# ATSAML22G18A register map
Vendor: Atmel Corporation; Series: SAML22; File version: A
CPU: CM0+ r0p1, little endian, MPU, no FPU, VTOR, 2 interrupt priority bits
Registers are 32-bit, read-write, reset 0x0 unless marked. A register's access mark holds for its fields unless they carry their own. Offsets are from the block's base; [hi:lo] are bit positions; {n}, {i} and the like mark numbered series; 'fields as' and 'values as' point back to an identical list.

## OSC32KCTRL — 32k Oscillators Control
Base 0x40001400; register names take the prefix OSC32KCTRL_
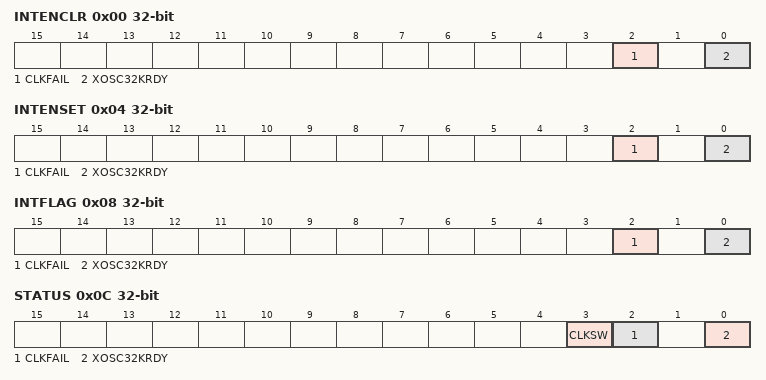
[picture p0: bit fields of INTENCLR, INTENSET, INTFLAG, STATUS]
0x00 INTENCLR — Interrupt Enable Clear
  [2] CLKFAIL — XOSC32K Clock Failure Detector Interrupt Enable
  [0] XOSC32KRDY — XOSC32K Ready Interrupt Enable
0x04 INTENSET — Interrupt Enable Set
  fields as INTENCLR
0x08 INTFLAG — Interrupt Flag Status and Clear
  [2] CLKFAIL — XOSC32K Clock Failure Detector
  [0] XOSC32KRDY — XOSC32K Ready
0x0C STATUS ro — Power and Clocks Status
  [3] CLKSW — XOSC32K Clock switch
  [2] CLKFAIL — XOSC32K Clock Failure Detector
  [0] XOSC32KRDY — XOSC32K Ready
0x10 RTCCTRL 8-bit — RTC Clock Selection
  [2:0] RTCSEL
    0=ULP1K (1.024kHz from 32kHz internal ULP oscillator); 1=ULP32K (32.768kHz from 32kHz internal ULP oscillator); 2=OSC1K (1.024kHz from 32.768kHz internal oscillator); 3=OSC32K (32.768kHz from 32.768kHz internal oscillator); 4=XOSC1K (1.024kHz from 32.768kHz internal oscillator); 5=XOSC32K (32.768kHz from 32.768kHz external crystal oscillator)
0x11 SLCDCTRL 8-bit — SLCD Clock Selection
  [0] SLCDSEL
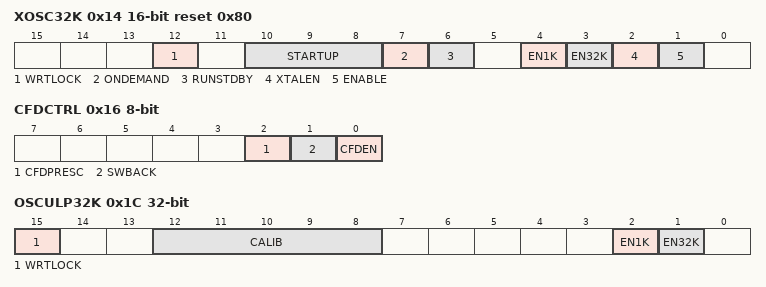
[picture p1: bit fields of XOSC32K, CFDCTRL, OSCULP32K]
0x14 XOSC32K 16-bit reset 0x80 — 32kHz External Crystal Oscillator (XOSC32K) Control
  [12] WRTLOCK — Write Lock
  [10:8] STARTUP — Oscillator Start-Up Time
  [7] ONDEMAND — On Demand Control
  [6] RUNSTDBY — Run in Standby
  [4] EN1K — 1kHz Output Enable
  [3] EN32K — 32kHz Output Enable
  [2] XTALEN — Crystal Oscillator Enable
  [1] ENABLE — Oscillator Enable
0x16 CFDCTRL 8-bit — Clock Failure Detector Control
  [2] CFDPRESC — Clock Failure Detector Prescaler
  [1] SWBACK — Clock Switch Back
  [0] CFDEN — Clock Failure Detector Enable
0x17 EVCTRL 8-bit — Event Control
  [0] CFDEO — Clock Failure Detector Event Output Enable
0x1C OSCULP32K — 32kHz Ultra Low Power Internal Oscillator (OSCULP32K) Control
  [15] WRTLOCK — Write Lock
  [12:8] CALIB — Oscillator Calibration
  [2] EN1K — Enable Out 1k
  [1] EN32K — Enable Out 32k

## PAC — Peripheral Access Controller
Base 0x40000000; register names take the prefix PAC_
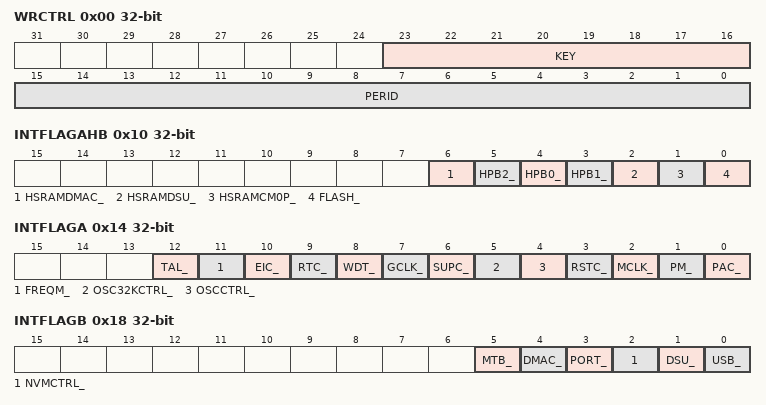
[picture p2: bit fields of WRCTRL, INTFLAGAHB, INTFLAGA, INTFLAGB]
0x00 WRCTRL — Write control
  [23:16] KEY — Peripheral access control key
    0=OFF (No action); 1=CLR (Clear protection); 2=SET (Set protection); 3=SETLCK (Set and lock protection)
  [15:0] PERID — Peripheral identifier
0x04 EVCTRL 8-bit — Event control
  [0] ERREO — Peripheral acess error event output
0x08 INTENCLR 8-bit — Interrupt enable clear
  [0] ERR — Peripheral access error interrupt disable
0x09 INTENSET 8-bit — Interrupt enable set
  [0] ERR — Peripheral access error interrupt enable
0x10 INTFLAGAHB — Bridge interrupt flag status
  [6] HSRAMDMAC_, [5] HPB2_, [4] HPB0_, [3] HPB1_, [2] HSRAMDSU_, [1] HSRAMCM0P_, [0] FLASH_
0x14 INTFLAGA — Peripheral interrupt flag status - Bridge A
  [12] TAL_, [11] FREQM_, [10] EIC_, [9] RTC_, [8] WDT_, [7] GCLK_, [6] SUPC_, [5] OSC32KCTRL_, [4] OSCCTRL_, [3] RSTC_, [2] MCLK_, [1] PM_, [0] PAC_
0x18 INTFLAGB — Peripheral interrupt flag status - Bridge B
  [5] MTB_, [4] DMAC_, [3] PORT_, [2] NVMCTRL_, [1] DSU_, [0] USB_
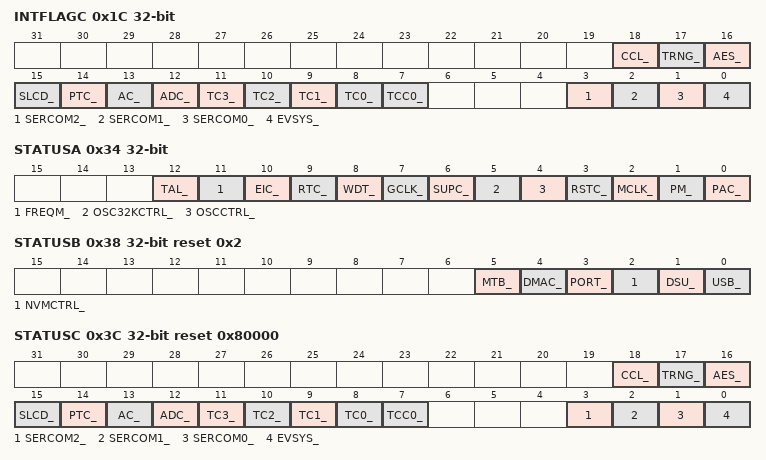
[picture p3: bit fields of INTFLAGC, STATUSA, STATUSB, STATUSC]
0x1C INTFLAGC — Peripheral interrupt flag status - Bridge C
  [18] CCL_, [17] TRNG_, [16] AES_, [15] SLCD_, [14] PTC_, [13] AC_, [12] ADC_, [n+8] TC{n}_ (n=0..3), [7] TCC0_, [3] SERCOM2_, [2] SERCOM1_, [1] SERCOM0_, [0] EVSYS_
0x34 STATUSA ro — Peripheral write protection status - Bridge A
  [12] TAL_ — TAL APB Protect Enable
  [11] FREQM_ — FREQM APB Protect Enable
  [10] EIC_ — EIC APB Protect Enable
  [9] RTC_ — RTC APB Protect Enable
  [8] WDT_ — WDT APB Protect Enable
  [7] GCLK_ — GCLK APB Protect Enable
  [6] SUPC_ — SUPC APB Protect Enable
  [5] OSC32KCTRL_ — OSC32KCTRL APB Protect Enable
  [4] OSCCTRL_ — OSCCTRL APB Protect Enable
  [3] RSTC_ — RSTC APB Protect Enable
  [2] MCLK_ — MCLK APB Protect Enable
  [1] PM_ — PM APB Protect Enable
  [0] PAC_ — PAC APB Protect Enable
0x38 STATUSB ro reset 0x2 — Peripheral write protection status - Bridge B
  [5] MTB_ — MTB APB Protect Enable
  [4] DMAC_ — DMAC APB Protect Enable
  [3] PORT_ — PORT APB Protect Enable
  [2] NVMCTRL_ — NVMCTRL APB Protect Enable
  [1] DSU_ — DSU APB Protect Enable
  [0] USB_ — USB APB Protect Enable
0x3C STATUSC ro reset 0x80000 — Peripheral write protection status - Bridge C
  [18] CCL_ — CCL APB Protect Enable
  [17] TRNG_ — TRNG APB Protect Enable
  [16] AES_ — AES APB Protect Enable
  [15] SLCD_ — SLCD APB Protect Enable
  [14] PTC_ — PTC APB Protect Enable
  [13] AC_ — AC APB Protect Enable
  [12] ADC_ — ADC APB Protect Enable
  [n+8] TC{n}_ (n=0..3) — TC{n} APB Protect Enable
  [7] TCC0_ — TCC0 APB Protect Enable
  [3] SERCOM2_ — SERCOM2 APB Protect Enable
  [2] SERCOM1_ — SERCOM1 APB Protect Enable
  [1] SERCOM0_ — SERCOM0 APB Protect Enable
  [0] EVSYS_ — EVSYS APB Protect Enable

## Notices in the file
Atmel Microcontroller Software Support
Copyright (c) 2015, Atmel Corporation
All rights reserved.
Redistribution and use in source and binary forms, with or without
modification, are permitted provided that the following condition is met:
- Redistributions of source code must retain the above copyright notice,
this list of conditions and the disclaimer below.
Atmel's name may not be used to endorse or promote products derived from
this software without specific prior written permission.
DISCLAIMER: THIS SOFTWARE IS PROVIDED BY ATMEL "AS IS" AND ANY EXPRESS OR
IMPLIED WARRANTIES, INCLUDING, BUT NOT LIMITED TO, THE IMPLIED WARRANTIES OF
MERCHANTABILITY, FITNESS FOR A PARTICULAR PURPOSE AND NON-INFRINGEMENT ARE
DISCLAIMED. IN NO EVENT SHALL ATMEL BE LIABLE FOR ANY DIRECT, INDIRECT,
INCIDENTAL, SPECIAL, EXEMPLARY, OR CONSEQUENTIAL DAMAGES (INCLUDING, BUT NOT
LIMITED TO, PROCUREMENT OF SUBSTITUTE GOODS OR SERVICES; LOSS OF USE, DATA,
OR PROFITS; OR BUSINESS INTERRUPTION) HOWEVER CAUSED AND ON ANY THEORY OF
LIABILITY, WHETHER IN CONTRACT, STRICT LIABILITY, OR TORT (INCLUDING
NEGLIGENCE OR OTHERWISE) ARISING IN ANY WAY OUT OF THE USE OF THIS SOFTWARE,
EVEN IF ADVISED OF THE POSSIBILITY OF SUCH DAMAGE.
